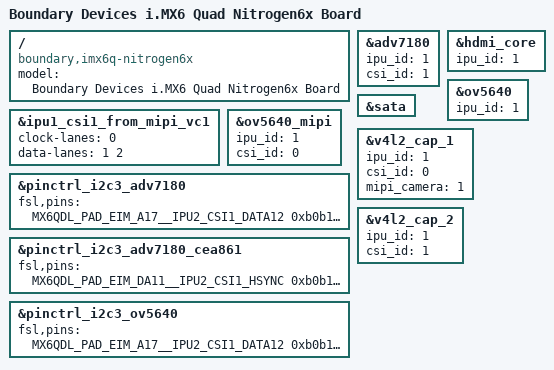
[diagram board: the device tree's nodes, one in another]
// SPDX-License-Identifier: GPL-2.0 OR X11
/*
 * Copyright 2013-2016 Boundary Devices, Inc.
 * Copyright 2012 Freescale Semiconductor, Inc.
 * Copyright 2011 Linaro Ltd.
 */

/dts-v1/;
#include "imx6q.dtsi"
#include "imx6qdl-nitrogen6x.dtsi"

/ {
	model = "Boundary Devices i.MX6 Quad Nitrogen6x Board";
	compatible = "boundary,imx6q-nitrogen6x", "fsl,imx6q";
};

&adv7180 {
	ipu_id = <1>;
	csi_id = <1>;
};

&hdmi_core {
	ipu_id = <1>;
};

&ipu1_csi1_from_mipi_vc1 {
	clock-lanes = <0>;
	data-lanes = <1 2>;
};

&ov5640 {
	ipu_id = <1>;
};

&ov5640_mipi {
	ipu_id = <1>;
	csi_id = <0>;
};

&pinctrl_i2c3_adv7180 {
	fsl,pins = <
		MX6QDL_PAD_EIM_A17__IPU2_CSI1_DATA12	0xb0b1
		MX6QDL_PAD_EIM_A18__IPU2_CSI1_DATA13	0xb0b1
		MX6QDL_PAD_EIM_A19__IPU2_CSI1_DATA14	0xb0b1
		MX6QDL_PAD_EIM_A20__IPU2_CSI1_DATA15	0xb0b1
		MX6QDL_PAD_EIM_A21__IPU2_CSI1_DATA16	0xb0b1
		MX6QDL_PAD_EIM_A22__IPU2_CSI1_DATA17	0xb0b1
		MX6QDL_PAD_EIM_A23__IPU2_CSI1_DATA18	0xb0b1
		MX6QDL_PAD_EIM_EB2__IPU2_CSI1_DATA19	0xb0b1
		MX6QDL_PAD_EIM_A16__IPU2_CSI1_PIXCLK	0xb0b1
       >;
};

&pinctrl_i2c3_adv7180_cea861 {
	fsl,pins = <
		MX6QDL_PAD_EIM_DA11__IPU2_CSI1_HSYNC	0xb0b1
		MX6QDL_PAD_EIM_DA12__IPU2_CSI1_VSYNC	0xb0b1
	>;
};

&pinctrl_i2c3_ov5640 { /* parallel camera */
	fsl,pins = <
		MX6QDL_PAD_EIM_A17__IPU2_CSI1_DATA12	0xb0b1
		MX6QDL_PAD_EIM_A18__IPU2_CSI1_DATA13	0xb0b1
		MX6QDL_PAD_EIM_A19__IPU2_CSI1_DATA14	0xb0b1
		MX6QDL_PAD_EIM_A20__IPU2_CSI1_DATA15	0xb0b1
		MX6QDL_PAD_EIM_A21__IPU2_CSI1_DATA16	0xb0b1
		MX6QDL_PAD_EIM_A22__IPU2_CSI1_DATA17	0xb0b1
		MX6QDL_PAD_EIM_A23__IPU2_CSI1_DATA18	0xb0b1
		MX6QDL_PAD_EIM_EB2__IPU2_CSI1_DATA19	0xb0b1
		MX6QDL_PAD_EIM_DA10__IPU2_CSI1_DATA_EN	0xb0b1
		MX6QDL_PAD_EIM_A16__IPU2_CSI1_PIXCLK	0xb0b1
		MX6QDL_PAD_EIM_DA11__IPU2_CSI1_HSYNC	0xb0b1
		MX6QDL_PAD_EIM_DA12__IPU2_CSI1_VSYNC	0xb0b1
	>;
};

&sata {
	status = "okay";
};

/* ov5640_mipi */
&v4l2_cap_1 {
	ipu_id = <1>;
	csi_id = <0>;
	mipi_camera = <1>;
};

/* adv7180, ov5640 */
&v4l2_cap_2 {
	ipu_id = <1>;
	csi_id = <1>;
};
